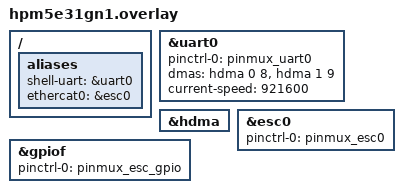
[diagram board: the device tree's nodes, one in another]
#include <dt-bindings/pinctrl/hpmicro-pinctrl-common.h>
#include <dt-bindings/gpio/gpio.h>

/ {
    aliases {
        shell-uart = &uart0;
        ethercat0  = &esc0;
    };
};

&uart0 {
    pinctrl-0 = <&pinmux_uart0>;
    pinctrl-names = "default";
    dmas = <&hdma 0 8>, <&hdma 1 9>;
    dma-names = "rx", "tx";
    current-speed = <921600>;
    status = "okay";
};

&hdma {
    status = "okay";
};

&esc0 {
    pinctrl-0 = <&pinmux_esc0>;
    pinctrl-names = "default";
    status = "okay";
};

&gpiof {
    pinctrl-0 = <&pinmux_esc_gpio>;
    pinctrl-names = "default";
    status = "okay";
};
